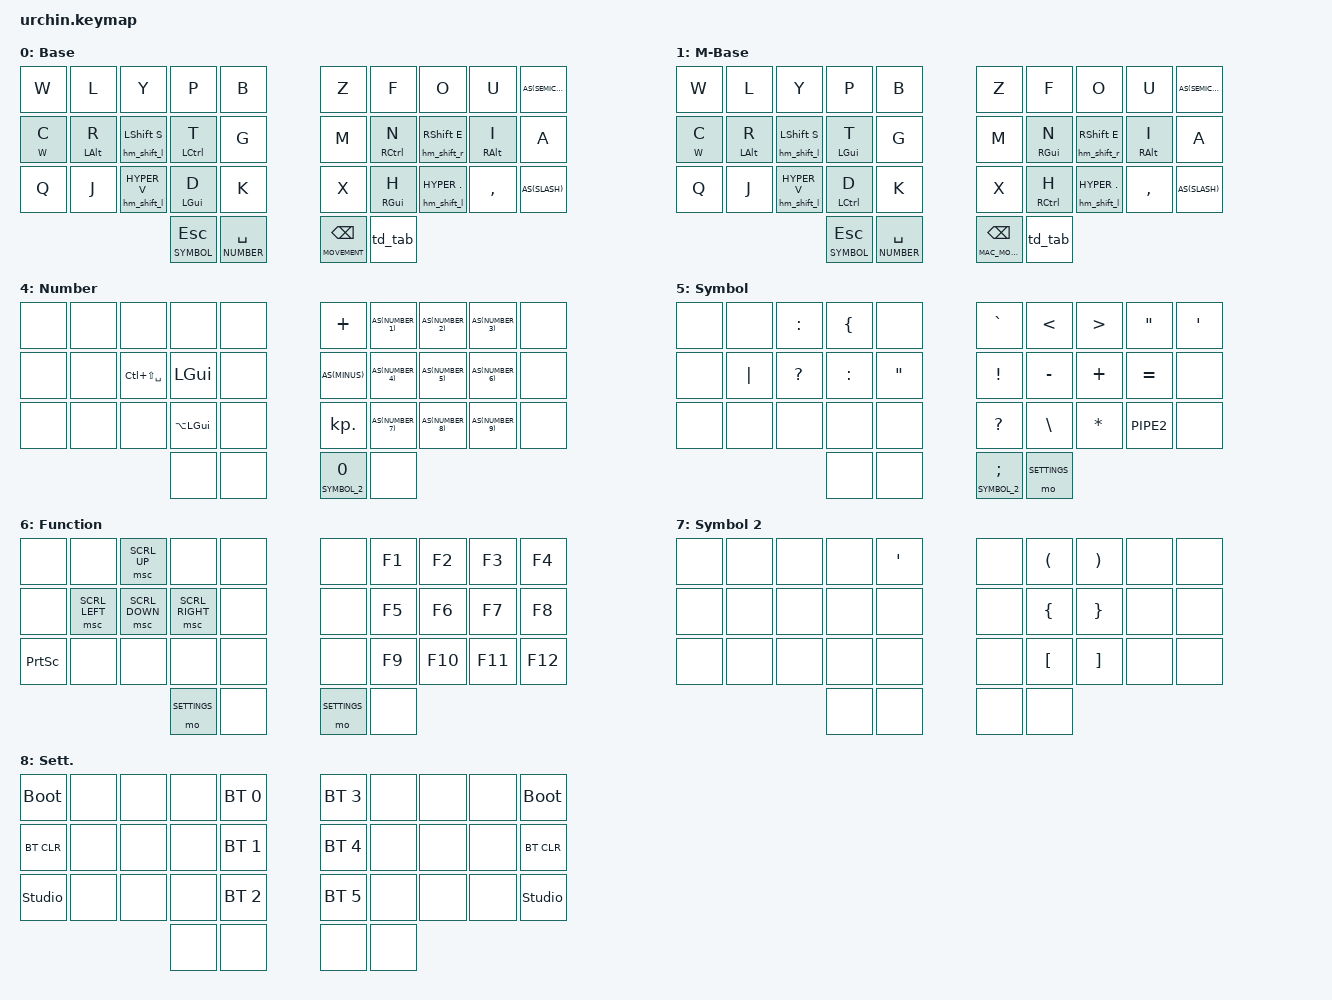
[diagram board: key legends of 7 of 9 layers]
/*
 * Copyright (c) 2020 Tantanok221 
 *
 * SPDX-License-Identifier: MIT
 */

#include <behaviors.dtsi>
#include <dt-bindings/zmk/keys.h>
#include <dt-bindings/zmk/bt.h>
#include <dt-bindings/zmk/outputs.h>
#include <dt-bindings/zmk/pointing.h>

#include "includes/timeless_homerow_mods.dtsi"
// urob helper 
#include "zmk-helpers/helper.h"

// Source desired key-position labels
#include "zmk-helpers/key-labels/34.h"

 
// Global Definitions
#define HOVER_TIMEOUT 50

// Layer definitions
#define BASE 0
#define MAC_BASE 1 
#define MOVEMENT 2 
#define MAC_MOVEMENT 3 
#define NUMBER 4
#define SYMBOL 5 
#define FUNCTION 6 
#define SYMBOL_2 7 
#define SETTINGS 8 
// -----------------

// Macro
#define AS(keycode) &as LS(keycode) keycode  
#define HYPER LC(LA(LS(LGUI)))

&sk {
	// don't release mods on other mods presses
	ignore-modifiers;
};


/ {
	behaviors {
    as: auto_shift {
      compatible = "zmk,behavior-hold-tap";
      #binding-cells = <2>;
      tapping_term_ms = <135>;
      quick_tap_ms = <0>;
      flavor = "tap-preferred";
      bindings = <&kp>, <&kp>;
    };


  td_tab: tap_dance_0 {
      compatible = "zmk,behavior-tap-dance";
      #binding-cells = <0>;
      tapping-term-ms = <200>;
      bindings = <&lt FUNCTION TAB>, <&kp LC(LA(LS(TAB)))>;
    };
  };

	macros {
    ou_combo: ou_combo {
    compatible = "zmk,behavior-macro";
            #binding-cells = <0>;
            bindings
                = <&macro_press &kp O &kp U>;
   };
	};

	combos {
		compatible = "zmk,combos";
    combo_launcher {
      timeout-ms = <HOVER_TIMEOUT>;
      key-positions = <RM1 RM2 RM3>;
      layers = <0>;
      bindings = <&kp LC(SPACE)>;
    };

	  combo_mac_launcher {
      timeout-ms = <HOVER_TIMEOUT>;
      key-positions = <RM1 RM2 RM3>;
      layers = <1>;
      bindings = <&kp LG(SPACE)>;
    };
			
    combo_language {
      timeout-ms = <HOVER_TIMEOUT>;
      key-positions = <LM1 LM2 LM3>;
      layers = <0>;
      bindings = <&kp LC(LS(SPACE))>;
    };

    combo_mac_language {
      timeout-ms = <HOVER_TIMEOUT>;
      key-positions = <LM1 LM2 LM3>;
      layers = <1>;
      bindings = <&kp GLOBE>; 
    };

    combo_enter {
      timeout-ms = <HOVER_TIMEOUT>;
      key-positions = <LH0 RH0>;
      layers = <0 1>;
      bindings = <&kp ENTER>;
    };
	
    combo_esc {
      timeout-ms = <HOVER_TIMEOUT>;
      key-positions = <LT1 LT2>;
      layers = <0 1>;
      bindings = <&kp ESC>;
    };

    combo_q {
      timeout-ms = <HOVER_TIMEOUT>;
      key-positions = <LB3 LB2>;
      layers = <0 1>;
      bindings = <&kp Q>;
    };

    combo_w {
      timeout-ms = <HOVER_TIMEOUT>;
      key-positions = <LT3 LT2>;
      layers = <0 1>;
      bindings = <&kp W>;
    };

    combo_repeat {
      timeout-ms = <HOVER_TIMEOUT>;
      key-positions = <RT1 RT2>;
      layers = <0 1>;
      bindings = <&key_repeat>;
    };

    combo_helperou {
      timeout-ms = <HOVER_TIMEOUT>;
      key-positions = <RT2 RT3>;
      layers = <0 1>;
      bindings = <&ou_combo>;
    };

    combo_settingl {
      timeout-ms = <HOVER_TIMEOUT>;
      key-positions = <LH1 LH0>;
      layers = <0 1>;
      bindings = <&mo SETTINGS>;
    };
    
    combo_settingr {
      timeout-ms = <HOVER_TIMEOUT>;
      key-positions = <RH1 RH0>;
      layers = <0 1>;
      bindings = <&mo SETTINGS>;
    };


	};

    keymap {
        compatible = "zmk,keymap";
        
        // Base alpha layer
        default_layer {
            label = "Base";
            bindings = <
                &kp W      &kp L                 &kp Y                  &kp P            &kp B             &kp Z   &kp F                  &kp O                   &kp U            AS(SEMICOLON)
                &mt W C    &hm_l LALT R          &hm_shift_l LSHIFT S   &hm_l LCTRL T    &kp G             &kp M   &hm_r RCTRL N          &hm_shift_r RSHIFT E    &hm_r RALT I     &kp A
                &kp Q      &kp J                 &hm_shift_l HYPER V    &hm_l LGUI D     &kp K             &kp X   &hm_r RGUI H           &hm_shift_l HYPER DOT   &kp COMMA        AS(SLASH)
                                                                        &lt SYMBOL ESC   &lt NUMBER SPACE  &lt MOVEMENT BSPC       &td_tab
            >;
        };
 
        // Base mac alpha layer
        defaultmac_layer {
            label = "M-Base";
            bindings = <
                &kp W      &kp L                 &kp Y                  &kp P             &kp B             &kp Z   &kp F                  &kp O                   &kp U            AS(SEMICOLON)
                &mt W C    &hm_l LALT R          &hm_shift_l LSHIFT S   &hm_l LGUI T      &kp G             &kp M   &hm_r RGUI N           &hm_shift_r RSHIFT E    &hm_r RALT I     &kp A
                &kp Q      &kp J                 &hm_shift_l HYPER V    &hm_l LCTRL D     &kp K             &kp X   &hm_r RCTRL H          &hm_shift_l HYPER DOT   &kp COMMA        AS(SLASH)
                                                                        &lt SYMBOL ESC    &lt NUMBER SPACE  &lt MAC_MOVEMENT BSPC       &td_tab
            >;
        };

        // Movement layer
        movement_layer {
            label = "Movement";
            bindings = <
                &none    &kp LC(LEFT)      &kp UP    &kp LC(RIGHT)       &kp PG_UP     &none    &kp KP_NUMBER_0    &kp DOLLAR         &none                &none 
                &none    &kp LEFT          &kp DOWN  &kp RIGHT           &kp PG_DN     &none    &kp LC(LA(LSHIFT)) &kp LC(LS(LGUI))   &kp LC(LA(LS(LGUI))) &none
                &none    &kp LC(D)         &kp LC(X) &kp LC(C)           &kp LC(V)     &none    &kp LCTRL          &kp LSHIFT         &kp LALT             &kp LGUI
                                                     &none               &kp LSHIFT    &none    &none 
            >;
        };

        // Movement mac layer
        macmovement_layer {
            label = "M-Movement";
            bindings = <
                &none    &kp LG(LEFT)      &kp UP    &kp LG(RIGHT)       &kp PG_UP     &none    &kp KP_NUMBER_0    &kp DOLLAR         &none                &none 
                &none    &kp LEFT          &kp DOWN  &kp RIGHT           &kp PG_DN     &none    &kp LC(LA(LSHIFT)) &kp LC(LS(LGUI))   &kp LC(LA(LS(LGUI))) &none
                &none    &kp LG(D)         &kp LG(X) &kp LG(C)           &kp LG(V)     &none    &kp LCTRL          &kp LSHIFT         &kp LALT             &kp LGUI
                                                     &none               &kp LSHIFT    &none    &none 
            >;
        };

        // Number layer
        number_layer {
            label = "Number";
            bindings = <
                &none    &none    &none             &none        &none         &kp PLUS   AS(NUMBER_1)  AS(NUMBER_2)  AS(NUMBER_3) &none 
                &none    &none    &kp LC(LS(SPACE)) &kp LGUI     &none         AS(MINUS)  AS(NUMBER_4) AS(NUMBER_5) AS(NUMBER_6) &none
                &none    &none    &none             &kp LA(LGUI) &none         &kp KP_DOT AS(NUMBER_7) AS(NUMBER_8) AS(NUMBER_9) &none
                                                   &none        &none         &lt SYMBOL_2 NUMBER_0    &none 
            >;
        };

        // Symbol layer
        symbol_layer {
            label = "Symbol";
            bindings = <
                &none    &none     &kp COLON    &kp LEFT_BRACE &none         &kp GRAVE    &kp LT    &kp GT    &kp DQT    &kp SQT
                &none    &kp PIPE &kp QUESTION &kp COLON      &kp DQT       &kp EXCL     &kp MINUS &kp PLUS  &kp EQUAL  &none
                &none    &none     &none        &none          &none         &kp QUESTION &kp BSLH  &kp STAR  &kp PIPE2  &none
                                               &none          &none         &lt SYMBOL_2 SEMICOLON  &mo SETTINGS 
            >;
        };

        // Function layer
        function_layer {
            label = "Function";
            bindings = <
                &none    &none          &msc SCRL_UP   &none           &none         &none    &kp F1  &kp F2  &kp F3  &kp F4 
                &none    &msc SCRL_LEFT &msc SCRL_DOWN &msc SCRL_RIGHT &none         &none    &kp F5  &kp F6  &kp F7  &kp F8
                &kp PSCRN &none          &none          &none           &none         &none    &kp F9  &kp F10 &kp F11 &kp F12
                                                      &mo SETTINGS &none         &mo SETTINGS &none 
            >;
        };

        // Symbol 2 layer
        symbol2_layer {
            label = "Symbol 2";
            bindings = <
                &none    &none    &none    &none    &kp SQT       &none    &kp LPAR &kp RPAR &none    &none 
                &none    &none    &none    &none    &none         &none    &kp LBRC &kp RBRC &none    &none
                &none    &none    &none    &none    &none         &none    &kp LBKT &kp RBKT &none    &none
                                          &none    &none         &none    &none 
            >;
        };

        // Used to change the keyboard's settings.
        settings_layer {
            label = "Sett.";
            bindings = <
                &bootloader    &none    &none    &none        &bt BT_SEL 0     &bt BT_SEL 3 &none    &none    &none    &bootloader 
                &bt BT_CLR     &none    &none    &none        &bt BT_SEL 1     &bt BT_SEL 4 &none    &none    &none    &bt BT_CLR
                &studio_unlock &none    &none    &none        &bt BT_SEL 2     &bt BT_SEL 5 &none    &none    &none    &studio_unlock
                                                 &none        &none            &none        &none 
            >;
        };
    };
};
